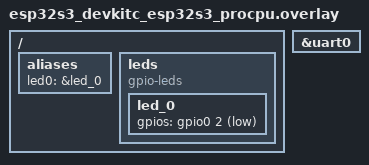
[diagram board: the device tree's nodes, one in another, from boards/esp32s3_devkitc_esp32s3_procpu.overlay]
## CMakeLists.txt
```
cmake_minimum_required(VERSION 3.28.0)

list(APPEND BOARD_ROOT ${CMAKE_CURRENT_SOURCE_DIR}/..)

find_package(Zephyr REQUIRED HINTS $ENV{ZEPHYR_BASE})
project(my_zephyr_app)

target_sources(app PRIVATE src/main.cpp)
```

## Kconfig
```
menu "APP_HEARTBEAT_PERIOD_MS "
    visible if LED_SUBSYSTEM

config APP_HEARTBEAT_PERIOD_MS 
    int "led heartbeat period"
    default 500 
    range 100 2000
    
    
endmenu

source "Kconfig.zephyr"
```

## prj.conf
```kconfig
CONFIG_GPIO=y
CONFIG_LOG=y
CONFIG_APP_HEARTBEAT_PERIOD_MS=1000
CONFIG_HEAP_MEM_POOL_SIZE=16384
```

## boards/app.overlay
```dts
/{
    aliases{
        led0 = &app_led; // by node 
        labelled1 = "/leds/led_red" ; // by path
        };
    };
```

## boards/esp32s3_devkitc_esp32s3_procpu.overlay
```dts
/* Enable a disabled peripheral */
&uart0 {
    status = "okay";
};

/* Add an LED definition */
/ {
    aliases {
        led0 = &led_0;
    };

    leds {
        compatible = "gpio-leds";
        led_0: led_0 {
            gpios = <&gpio0 2 GPIO_ACTIVE_LOW>;
        };
    };
};
```

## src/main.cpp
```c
#include <stdio.h>
#include <zephyr/init.h>
#include <zephyr/kernel.h>

static int board_init_msg(void) {
    printf("Board Initialized\n");
    return 0;
}

SYS_INIT(board_init_msg, APPLICATION, 0);

int main(void) {
    printf("Hello World! %s\n", CONFIG_BOARD_TARGET);
    return 0;
}
```
